# RS1xxxx register map
Vendor: Silicon Lab Inc.; Series: ARMCM4; File version: 1.2
CPU: CM4 r1p0, little endian, MPU, FPU, 6 interrupt priority bits
Registers are 32-bit, read-write, reset 0x0 unless marked. A register's access mark holds for its fields unless they carry their own. Offsets are from the block's base; [hi:lo] are bit positions.

## FIM — FIM support fixed point Multiplications implemented through programmable shifting.
Base 0x24070000
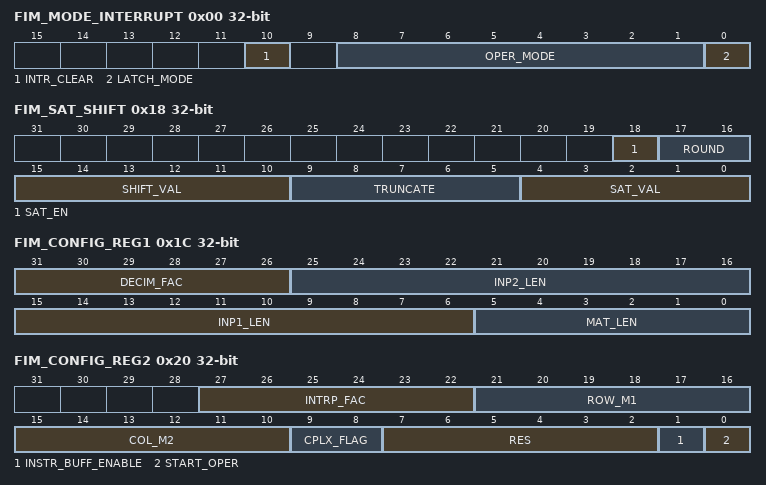
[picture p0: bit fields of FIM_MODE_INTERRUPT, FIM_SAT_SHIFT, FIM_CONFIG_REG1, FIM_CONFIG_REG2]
0x00 FIM_MODE_INTERRUPT — Configuration for FIM Operation Mode and Interrupt Control
  [10] INTR_CLEAR wo — Writing 1 to this bit clears the interrupt
    1=Enable to clear interrupt; 0=Disable to clear interrupt
  [8:1] OPER_MODE — Indicates the Mode of Operation to be performed.
  [0] LATCH_MODE — Enable latch mode
    1=Enable latch mode enable of FIM; 0=Disable latch mode enable of FIM
0x04 FIM_INP1_ADDR — This register used for COP input address for 0 register.
  [31:0] INP1_ADDR — Indicates the Start Address of 1st Input Data for FIM Operations
0x08 FIM_INP2_ADDR — This register used for COP input address for 1 register
  [31:0] INP2_ADDR — Indicates the Start Address of 2nd Input Data for FIM Operations
0x0C FIM_OUT_ADDR — Memory Offset Address for Output from FIM Operations
  [31:0] OUT_ADDR — Indicates the Start Address of Output Data for FIM Operations
0x10 FIM_SCALAR_POLE_DATA1 — Indicates the Input Scalar Data for Scalar Operations indicates the feedback coefficient for IIR Operations
  [31:0] SCALAR_POLE_DATA1 — Pole 0/Scalar Value
0x14 FIM_POLE_DATA2 — Feedback coefficient for IIR filter operation
  [31:0] POLE_DATA2 — Indicates the feedback coefficient for IIR Operations
0x18 FIM_SAT_SHIFT — Configuration for precision of Output Data for FIM Operations
  [18] SAT_EN — Saturation enable bit
  [17:16] ROUND
  [15:10] SHIFT_VAL — Indicates the number of bits to be right-shifted for Output Data
  [9:5] TRUNCATE
  [4:0] SAT_VAL — Indicates the number of MSB's to be saturated for Output Data
0x1C FIM_CONFIG_REG1 — Configuration Register for FIM Operations.
  [31:26] DECIM_FAC — Decimation Factor
  [25:16] INP2_LEN — Indicates the length of 2nd input for FIM Operations other than filtering (FIR, IIR) and Interpolation.
  [15:6] INP1_LEN — Indicates the length of 1st input for FIM Operations other than filtering (FIR, IIR) and Interpolation
  [5:0] MAT_LEN — Indicates the number of columns in 1st input for Matrix Multiplication. This is same as number of rows in 2nd input for Matrix Multiplication.
0x20 FIM_CONFIG_REG2 — Configuration Register for FIM Operations
  [27:22] INTRP_FAC — Indicates the Interpolation Factor
  [21:16] ROW_M1 — Indicates the number of rows in 1st input for Matrix Multiplication
  [15:10] COL_M2 — Indicates the number of columns in 2nd input for Matrix Multiplication
  [9:8] CPLX_FLAG — Complex Flag,not valid in matrix mode
    0=Real_Real (input1 and input2 both are real); 1=Real_Complex (input1 is real and input2 is complex); 2=Complex_Real (input1 is complex and input2 is real); 3=Complex_Complex (input1 and input2 both are complex)
  [7:2] RES ro — reserved5
  [1] INSTR_BUFF_ENABLE — Instruction buffer enable
  [0] START_OPER wo — Start trigger for the FIM operations,this is reset upon write register
    1=Enable start operation; 0=Disable start operation

## NWP_FSM — NWP FSM one register Structure
Base 0x41300110
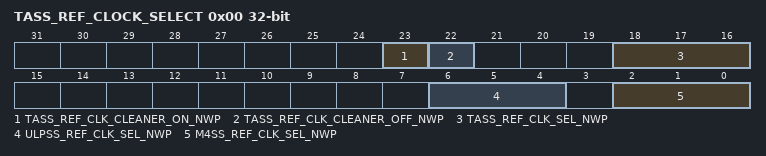
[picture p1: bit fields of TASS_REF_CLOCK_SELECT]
0x00 TASS_REF_CLOCK_SELECT
  [23] TASS_REF_CLK_CLEANER_ON_NWP, [22] TASS_REF_CLK_CLEANER_OFF_NWP, [18:16] TASS_REF_CLK_SEL_NWP, [6:4] ULPSS_REF_CLK_SEL_NWP, [2:0] M4SS_REF_CLK_SEL_NWP

## IR_Decoder — IR Decoder are used for the decoding the external ir sensor input.
Base 0x24040C00
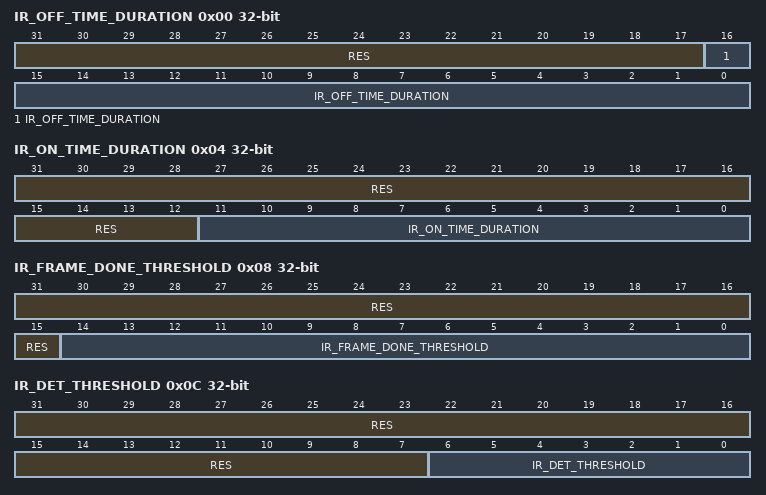
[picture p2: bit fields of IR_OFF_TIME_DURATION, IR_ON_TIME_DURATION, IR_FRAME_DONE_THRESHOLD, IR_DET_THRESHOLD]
0x00 IR_OFF_TIME_DURATION — This register used for IR sleep duration timer value.
  [31:17] RES ro — reserved5
  [16:0] IR_OFF_TIME_DURATION — This field define ir off time
0x04 IR_ON_TIME_DURATION — This register used for IR Detection duration timer value.
  [31:12] RES ro — reserved5
  [11:0] IR_ON_TIME_DURATION — This field define ir on time for ir detection on
0x08 IR_FRAME_DONE_THRESHOLD — This register used count with respect to 32KHz clock after not more toggle are expected to a given pattern.
  [31:15] RES ro — reserved5
  [14:0] IR_FRAME_DONE_THRESHOLD — count with respect to 32KHz clock after not more toggle are expected to a given pattern
0x0C IR_DET_THRESHOLD — This register used Minimum Number of edges to detected during on-time failing which IR detection is re-stated.
  [31:7] RES ro — reserved5
  [6:0] IR_DET_THRESHOLD — Minimum Number of edges to detected during on-time failing which IR detection is re-stated.
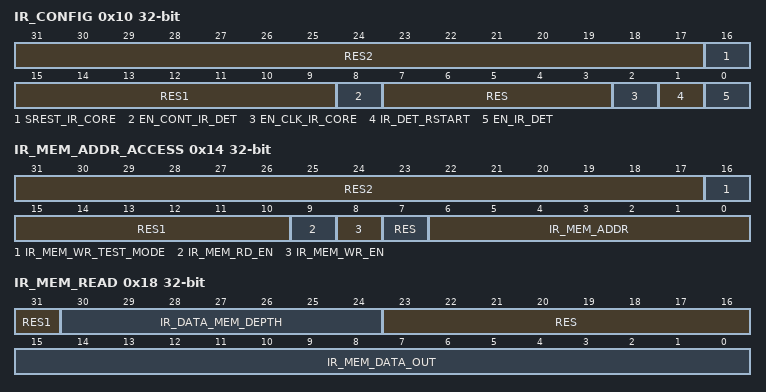
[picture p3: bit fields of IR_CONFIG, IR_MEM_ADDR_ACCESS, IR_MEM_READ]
0x10 IR_CONFIG — This register used to configure the ir structure for application purpose.
  [31:17] RES2 ro — reserved7
  [16] SREST_IR_CORE — This bit is used soft reset IR core block
  [15:9] RES1 ro — reserved6
  [8] EN_CONT_IR_DET — This bit is Enable continues IR detection,When enabled there will be no power cycling on External IR Sensor.
  [7:3] RES ro — reserved5
  [2] EN_CLK_IR_CORE — Enable 32KHz clock to IR Core bit ,if bit 1 then clock gating disable and bit is 0 then clock gating Enable
  [1] IR_DET_RSTART — Enable IR detection re-start logic bit if bit 1 then re-start.
  [0] EN_IR_DET — Enable IR detection logic bit if bit 1 then detection enable if 0 then not enable.
0x14 IR_MEM_ADDR_ACCESS — This register used to access memory address for application purpose.
  [31:17] RES2 — reserved2
  [16] IR_MEM_WR_TEST_MODE — IR memory write enable in test mode..
  [15:10] RES1 — reserved1
  [9] IR_MEM_RD_EN — This field used to IR memory read enable.
  [8] IR_MEM_WR_EN — IR memory write enable.
  [7] RES — reserved5
  [6:0] IR_MEM_ADDR — This field is used to IR read address.
0x18 IR_MEM_READ ro — This register used to IR Read data from memory.
  [31] RES1 — reserved6
  [30:24] IR_DATA_MEM_DEPTH — This field used to indicated valid number of IR Address in the memory to be read.
  [23:16] RES — reserved5
  [15:0] IR_MEM_DATA_OUT — This field is used to IR Read data from memory.
